# RP2040 register map
Vendor: Raspberry Pi; Series: RP; File version: 0.1
CPU: CM0PLUS r0p1, little endian, MPU, no FPU, VTOR, 2 interrupt priority bits, 32 interrupts
Registers are 32-bit, read-write, reset 0x0 unless marked. A register's access mark holds for its fields unless they carry their own. Offsets are from the block's base; [hi:lo] are bit positions; {n}, {i} and the like mark numbered series.

## SYSCFG — Register block for various chip control signals
Base 0x40004000
0x00 PROC0_NMI_MASK — Processor core 0 NMI source mask
  [31:0] PROC0_NMI_MASK — Set a bit high to enable NMI from that IRQ
0x04 PROC1_NMI_MASK — Processor core 1 NMI source mask
  [31:0] PROC1_NMI_MASK — Set a bit high to enable NMI from that IRQ
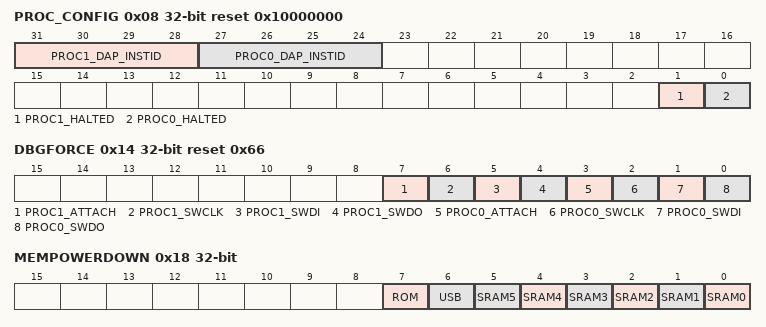
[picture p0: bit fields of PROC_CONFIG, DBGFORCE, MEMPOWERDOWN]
0x08 PROC_CONFIG reset 0x10000000 — Configuration for processors
  [31:28] PROC1_DAP_INSTID — Configure proc1 DAP instance ID. Recommend that this is NOT changed until you require debug access in multi-chip environment WARNING: do not set to 15 as this is reserved for RescueDP
  [27:24] PROC0_DAP_INSTID — Configure proc0 DAP instance ID. Recommend that this is NOT changed until you require debug access in multi-chip environment WARNING: do not set to 15 as this is reserved for RescueDP
  [1] PROC1_HALTED ro — Indication that proc1 has halted
  [0] PROC0_HALTED ro — Indication that proc0 has halted
0x0C PROC_IN_SYNC_BYPASS — For each bit, if 1, bypass the input synchronizer between that GPIO and the GPIO input register in the SIO. The input synchronizers should generally be unbypassed, to avoid injecting metastabilities into processors. If you're feeling brave, you can bypass to save two cycles of input latency. This register applies to GPIO 0...29.
  [29:0] PROC_IN_SYNC_BYPASS
0x10 PROC_IN_SYNC_BYPASS_HI — For each bit, if 1, bypass the input synchronizer between that GPIO and the GPIO input register in the SIO. The input synchronizers should generally be unbypassed, to avoid injecting metastabilities into processors. If you're feeling brave, you can bypass to save two cycles of input latency. This register applies to GPIO 30...35 (the QSPI IOs).
  [5:0] PROC_IN_SYNC_BYPASS_HI
0x14 DBGFORCE reset 0x66 — Directly control the SWD debug port of either processor
  [7] PROC1_ATTACH — Attach processor 1 debug port to syscfg controls, and disconnect it from external SWD pads.
  [6] PROC1_SWCLK — Directly drive processor 1 SWCLK, if PROC1_ATTACH is set
  [5] PROC1_SWDI — Directly drive processor 1 SWDIO input, if PROC1_ATTACH is set
  [4] PROC1_SWDO ro — Observe the value of processor 1 SWDIO output.
  [3] PROC0_ATTACH — Attach processor 0 debug port to syscfg controls, and disconnect it from external SWD pads.
  [2] PROC0_SWCLK — Directly drive processor 0 SWCLK, if PROC0_ATTACH is set
  [1] PROC0_SWDI — Directly drive processor 0 SWDIO input, if PROC0_ATTACH is set
  [0] PROC0_SWDO ro — Observe the value of processor 0 SWDIO output.
0x18 MEMPOWERDOWN — Control power downs to memories. Set high to power down memories. Use with extreme caution
  [7] ROM, [6] USB, [n] SRAM{n} (n=0..5)

## SYSINFO
Base 0x40000000
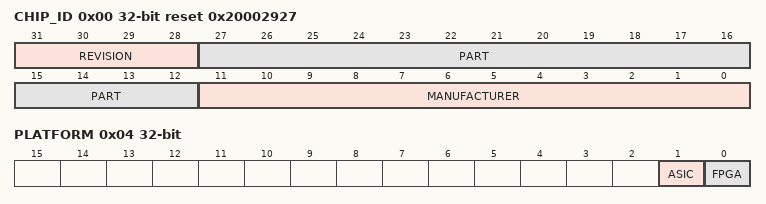
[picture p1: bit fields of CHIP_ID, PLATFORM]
0x00 CHIP_ID reset 0x20002927 — JEDEC JEP-106 compliant chip identifier.
  [31:28] REVISION ro, [27:12] PART ro, [11:0] MANUFACTURER ro
0x04 PLATFORM — Platform register. Allows software to know what environment it is running in.
  [1] ASIC ro, [0] FPGA ro
0x40 GITREF_RP2040 reset not defined — Git hash of the chip source. Used to identify chip version.
  [31:0] GITREF_RP2040 ro

## TBMAN — Testbench manager. Allows the programmer to know what platform their software is running on.
Base 0x4006C000
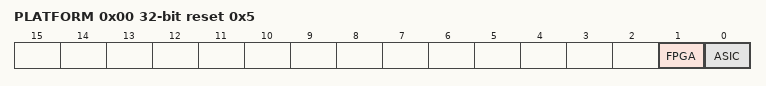
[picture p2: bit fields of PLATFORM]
0x00 PLATFORM reset 0x5 — Indicates the type of platform in use
  [1] FPGA ro — Indicates the platform is an FPGA
  [0] ASIC ro — Indicates the platform is an ASIC

## TIMER — Controls time and alarms time is a 64 bit value indicating the time in usec since power-on timeh is the top 32 bits of time & timel is the bottom 32 bits to change time write to timelw before timehw to read time read from timelr before timehr An alarm is set by setting alarm_enable and writing to the corresponding alarm register When an alarm is pending, the corresponding alarm_running signal will be high An alarm can be cancelled before it has finished by clearing the alarm_enable When an alarm fires, the corresponding alarm_irq is set and alarm_running is cleared To clear the interrupt write a 1 to the corresponding alarm_irq
Base 0x40054000
0x00 TIMEHW — Write to bits 63:32 of time always write timelw before timehw
  [31:0] TIMEHW wo
0x04 TIMELW — Write to bits 31:0 of time writes do not get copied to time until timehw is written
  [31:0] TIMELW wo
0x08 TIMEHR — Read from bits 63:32 of time always read timelr before timehr
  [31:0] TIMEHR ro
0x0C TIMELR — Read from bits 31:0 of time
  [31:0] TIMELR ro read-modifies
{0x10+4i} ALARM{i} (i=0..3) — Arm alarm {i}, and configure the time it will fire. Once armed, the alarm fires when TIMER_ALARM{i} == TIMELR. The alarm will disarm itself once it fires, and can be disarmed early using the ARMED status register.
0x20 ARMED — Indicates the armed/disarmed status of each alarm. A write to the corresponding ALARMx register arms the alarm. Alarms automatically disarm upon firing, but writing ones here will disarm immediately without waiting to fire.
  [3:0] ARMED write-1-clears
0x24 TIMERAWH — Raw read from bits 63:32 of time (no side effects)
  [31:0] TIMERAWH ro
0x28 TIMERAWL — Raw read from bits 31:0 of time (no side effects)
  [31:0] TIMERAWL ro
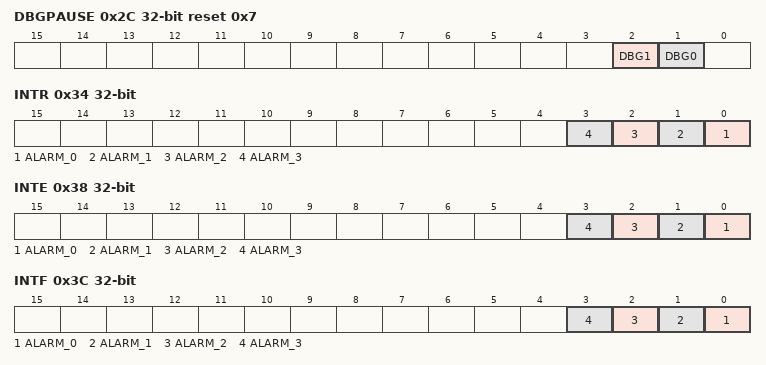
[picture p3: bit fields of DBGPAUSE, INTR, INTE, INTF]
0x2C DBGPAUSE reset 0x7 — Set bits high to enable pause when the corresponding debug ports are active
  [2] DBG1 — Pause when processor 1 is in debug mode
  [1] DBG0 — Pause when processor 0 is in debug mode
0x30 PAUSE — Set high to pause the timer
  [0] PAUSE
0x34 INTR — Raw Interrupts
  [n] ALARM_{n} write-1-clears (n=0..3)
0x38 INTE — Interrupt Enable
  [n] ALARM_{n} (n=0..3)
0x3C INTF — Interrupt Force
  [n] ALARM_{n} (n=0..3)
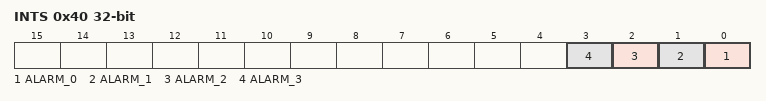
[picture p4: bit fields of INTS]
0x40 INTS — Interrupt status after masking & forcing
  [n] ALARM_{n} ro (n=0..3)
